# PIC16F1779 register map
Vendor: Microchip
Registers are 8-bit, read-write, reset 0x0 unless marked. A register's access mark holds for its fields unless they carry their own. Addresses are absolute, and some are shared; only a register's first bit layout is shown; [hi:lo] are bit positions; {n}, {i} and the like mark numbered series.

## SFR
0x00 INDF0 reset not defined — (power-on value xxxxxxxx)
0x01 INDF1 reset not defined — (power-on value xxxxxxxx)
0x02 PCL
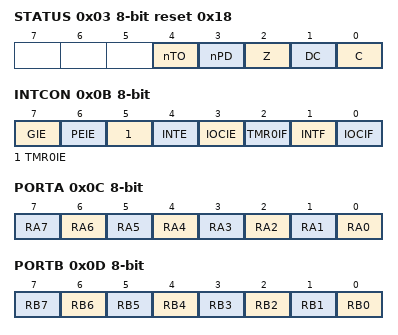
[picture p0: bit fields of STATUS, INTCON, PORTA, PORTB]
0x03 STATUS reset 0x18
  [4] nTO ro, [3] nPD ro, [2] Z, [1] DC, [0] C
0x04 FSR0L
0x05 FSR0H
0x06 FSR1L
0x07 FSR1H
0x08 BSR
  [4:0] BSR
0x09 WREG
  [7:0] WREG0
0x0A PCLATH
  [6:0] PCLATH
0x0B INTCON reset not defined — (power-on value 0000000x)
  [7] GIE, [6] PEIE, [5] TMR0IE, [4] INTE, [3] IOCIE, [2] TMR0IF, [1] INTF, [0] IOCIF ro
0x0C PORTA reset not defined — (power-on value xxxxxxxx)
  [n] RA{n} (n=0..7)
0x0D PORTB reset not defined — (power-on value xxxxxxxx)
  [n] RB{n} (n=0..7)
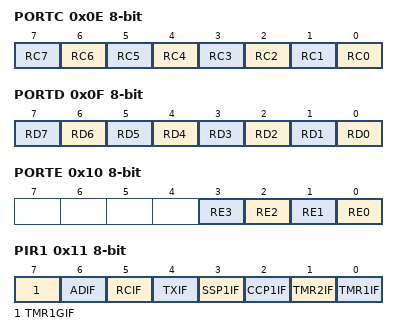
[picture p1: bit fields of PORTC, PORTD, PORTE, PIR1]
0x0E PORTC reset not defined — (power-on value xxxxxxxx)
  [n] RC{n} (n=0..7)
0x0F PORTD reset not defined — (power-on value xxxxxxxx)
  [n] RD{n} (n=0..7)
0x10 PORTE reset not defined — (power-on value ----xxxx)
  [n] RE{n} (n=0..3)
0x11 PIR1
  [7] TMR1GIF — Timer1 Gate Interrupt Flag bit
  [6] ADIF — A/D Converter Interrupt Flag bit
  [5] RCIF — EUSART Receive Interrupt Enable bit
  [4] TXIF — EUSART Transmit Interrupt Enable bit
  [3] SSP1IF — Synchronous Serial Port (MSSP) Interrupt Flag bit
  [2] CCP1IF
  [1] TMR2IF — TMR2 to PR2 Match Interrupt Flag bit
  [0] TMR1IF — TMR1 Overflow Interrupt Flag bit
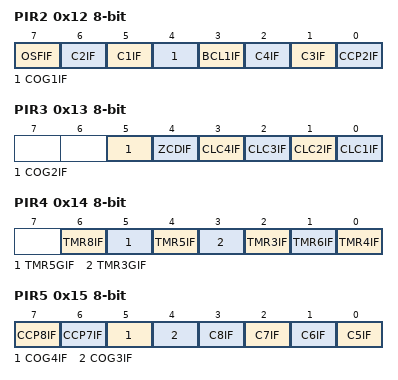
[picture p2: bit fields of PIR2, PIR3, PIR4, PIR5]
0x12 PIR2
  [7] OSFIF — Oscillator Fail Interrupt Enable bit
  [6] C2IF — Numerically Controlled Oscillator Flag bit
  [5] C1IF — Numerically Controlled Oscillator Flag bit
  [4] COG1IF
  [3] BCL1IF — MSSP Bus Collision Interrupt Flag bit
  [2] C4IF — Numerically Controlled Oscillator Flag bit
  [1] C3IF
  [0] CCP2IF
0x13 PIR3
  [5] COG2IF
  [4] ZCDIF
  [3] CLC4IF
  [2] CLC3IF — Configurable Logic Block Interrupt Flag
  [1] CLC2IF — Configurable Logic Block Interrupt Flag
  [0] CLC1IF — Configurable Logic Block Interrupt Flag
0x14 PIR4
  [6] TMR8IF, [5] TMR5GIF, [4] TMR5IF, [3] TMR3GIF, [2] TMR3IF, [1] TMR6IF, [0] TMR4IF
0x15 PIR5
  [7] CCP8IF, [6] CCP7IF, [5] COG4IF, [4] COG3IF, [n-5] C{n}IF (n=5..8)
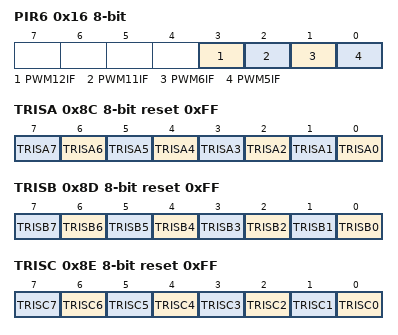
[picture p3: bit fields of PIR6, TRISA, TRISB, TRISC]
0x16 PIR6
  [3] PWM12IF, [2] PWM11IF, [1] PWM6IF, [0] PWM5IF
0x17 TMR0
0x8C TRISA reset 0xFF — PORTA Data Direction Control Register
  [n] TRISA{n} (n=0..7)
0x8D TRISB reset 0xFF
  [n] TRISB{n} (n=0..7)
0x8E TRISC reset 0xFF — PORTC Data Direction Control Register
  [n] TRISC{n} (n=0..7)
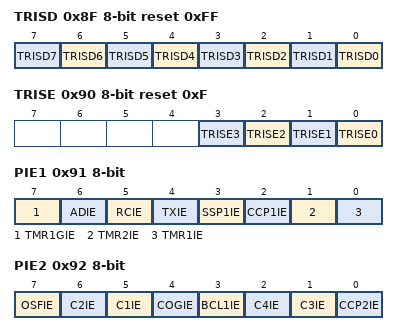
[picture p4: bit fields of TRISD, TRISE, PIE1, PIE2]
0x8F TRISD reset 0xFF
  [n] TRISD{n} (n=0..7)
0x90 TRISE reset 0xF
  [n] TRISE{n} (n=0..3)
0x91 PIE1 — Peripheral Interrupt Enable Register 1
  [7] TMR1GIE — Timer1 Gate Interrupt Enable bit
  [6] ADIE — A/D Converter Interrupt Enable bit
  [5] RCIE
  [4] TXIE
  [3] SSP1IE
  [2] CCP1IE
  [1] TMR2IE — TMR2 to PR2 Match Interrupt Enable bit
  [0] TMR1IE — TMR1 Overflow Interrupt Enable bit
0x92 PIE2 — Peripheral Interrupt Enable Register 2
  [7] OSFIE, [6] C2IE, [5] C1IE, [4] COGIE, [3] BCL1IE, [2] C4IE, [1] C3IE, [0] CCP2IE
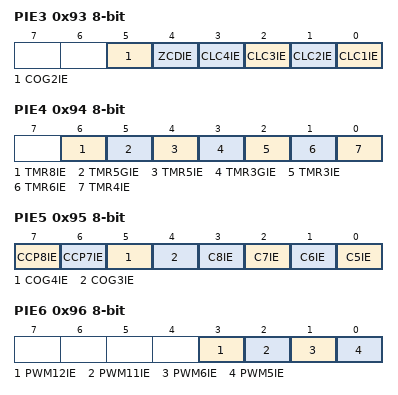
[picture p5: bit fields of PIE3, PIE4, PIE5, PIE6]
0x93 PIE3 — Peripheral Interrupt Enable Register 3
  [5] COG2IE, [4] ZCDIE, [n-1] CLC{n}IE (n=1..4)
0x94 PIE4
  [6] TMR8IE, [5] TMR5GIE, [4] TMR5IE, [3] TMR3GIE, [2] TMR3IE, [1] TMR6IE, [0] TMR4IE
0x95 PIE5 reset not defined — (power-on value x0x0xx00)
  [7] CCP8IE, [6] CCP7IE, [5] COG4IE, [4] COG3IE, [n-5] C{n}IE (n=5..8)
0x96 PIE6 reset not defined — (power-on value ----x000)
  [3] PWM12IE, [2] PWM11IE, [1] PWM6IE, [0] PWM5IE
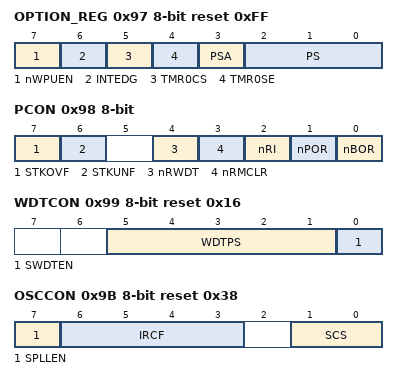
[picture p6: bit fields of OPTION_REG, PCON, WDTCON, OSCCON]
0x97 OPTION_REG reset 0xFF — Option Register
  [7] nWPUEN — Weak Pull-up Enable bit
  [6] INTEDG — Interrupt Edge Select bit
  [5] TMR0CS
  [4] TMR0SE — TMR0 Source Edge Select bit
  [3] PSA — Prescaler Active bit
  [2:0] PS
0x98 PCON reset not defined — Power Control Register (power-on value 00-111qq)
  [7] STKOVF — Stack Overflow Flag bit
  [6] STKUNF — Stack Underflow Flag bit
  [4] nRWDT
  [3] nRMCLR — MCLR Reset Flag bit
  [2] nRI — RESET Instruction Flag bit
  [1] nPOR — Power-on Reset Status bit
  [0] nBOR — Brown-out Reset Status bit
0x99 WDTCON reset 0x16 — Watchdog Timer Control Register
  [5:1] WDTPS
  [0] SWDTEN — Software Enable/Disable for Watch Dog Timer bit
0x9A OSCTUNE
  [5:0] TUN
0x9B OSCCON reset 0x38 — Oscillator Control Register
  [7] SPLLEN, [6:3] IRCF, [1:0] SCS
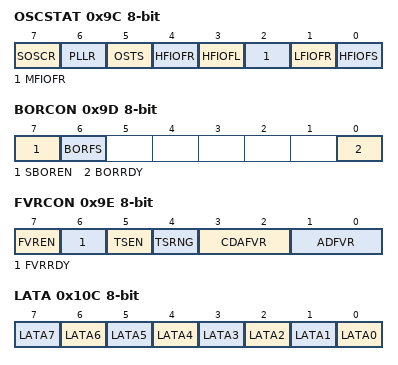
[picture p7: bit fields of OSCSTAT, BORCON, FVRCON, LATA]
0x9C OSCSTAT ro reset not defined — Oscillator Status Register (power-on value 0qq00q0q)
  [7] SOSCR
  [6] PLLR
  [5] OSTS — Oscillator Start-up Time-out Status bit
  [4] HFIOFR
  [3] HFIOFL
  [2] MFIOFR
  [1] LFIOFR — Low Freqency Internal Oscillator Ready bit
  [0] HFIOFS — Low Freqency Internal Oscillator Ready bit
0x9D BORCON reset not defined — (power-on value 10-----q)
  [7] SBOREN, [6] BORFS, [0] BORRDY ro
0x9E FVRCON reset not defined — (power-on value 0q000000)
  [7] FVREN, [6] FVRRDY ro, [5] TSEN, [4] TSRNG, [3:2] CDAFVR, [1:0] ADFVR
0x10C LATA reset not defined — (power-on value xxxxxxxx)
  [n] LATA{n} (n=0..7)
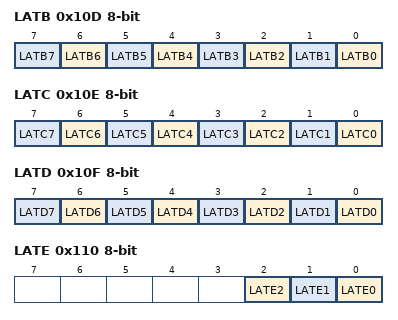
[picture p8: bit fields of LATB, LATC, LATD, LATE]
0x10D LATB reset not defined — (power-on value xxxxxxxx)
  [n] LATB{n} (n=0..7)
0x10E LATC reset not defined — (power-on value xxxxxxxx)
  [n] LATC{n} (n=0..7)
0x10F LATD reset not defined — (power-on value xxxxxxxx)
  [n] LATD{n} (n=0..7)
0x110 LATE reset not defined — (power-on value -----xxx)
  [2] LATE2, [1] LATE1, [0] LATE0
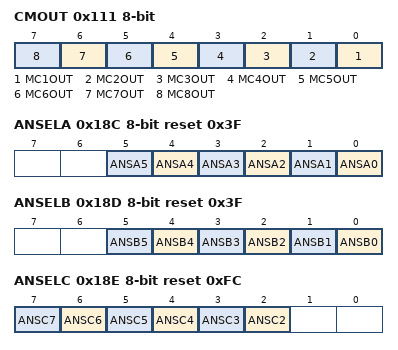
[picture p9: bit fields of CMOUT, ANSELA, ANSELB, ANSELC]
0x111 CMOUT ro
  [n-1] MC{n}OUT (n=1..8)
0x18C ANSELA reset 0x3F
  [n] ANSA{n} (n=0..5)
0x18D ANSELB reset 0x3F
  [n] ANSB{n} (n=0..5)
0x18E ANSELC reset 0xFC
  [n] ANSC{n} (n=2..7)
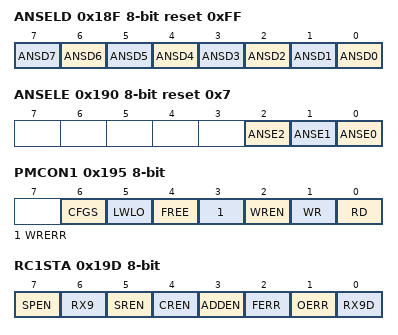
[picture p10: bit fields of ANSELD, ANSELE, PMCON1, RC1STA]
0x18F ANSELD reset 0xFF
  [n] ANSD{n} (n=0..7)
0x190 ANSELE reset 0x7
  [2] ANSE2, [1] ANSE1, [0] ANSE0
0x191 PMADRL
0x192 PMADRH reset 0x80
  [6:0] PMADRH
0x193 PMDATL reset not defined — (power-on value xxxxxxxx)
0x194 PMDATH reset not defined — (power-on value --xxxxxx)
  [5:0] PMDATH
0x195 PMCON1 reset not defined — (power-on value 1000x000)
  [6] CFGS — FLASH Program / Data EEPROM or Configuration Select bit
  [5] LWLO — Load Write Latches Only bit
  [4] FREE — Program FLASH Erase Enable bit
  [3] WRERR — Sequence Error Flag bit
  [2] WREN — Program/Erase Enable bit
  [1] WR — Write Control bit (can only be set)
  [0] RD — Read Control bit (can only be set)
0x196 PMCON2 wo
0x197 VREGCON reset 0x1
  [1] VREGPM
0x199 RC1REG ro
0x19A TX1REG
0x19B SP1BRGL
0x19C SP1BRGH
0x19D RC1STA
  [7] SPEN, [6] RX9, [5] SREN, [4] CREN, [3] ADDEN, [2] FERR ro, [1] OERR ro, [0] RX9D ro
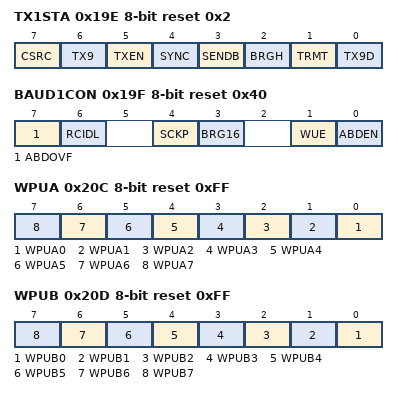
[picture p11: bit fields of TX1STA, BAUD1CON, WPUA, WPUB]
0x19E TX1STA reset 0x2
  [7] CSRC, [6] TX9, [5] TXEN, [4] SYNC, [3] SENDB, [2] BRGH, [1] TRMT ro, [0] TX9D
0x19F BAUD1CON reset 0x40
  [7] ABDOVF ro, [6] RCIDL ro, [4] SCKP, [3] BRG16, [1] WUE, [0] ABDEN
0x20C WPUA reset 0xFF
  [n] WPUA{n} (n=0..7)
0x20D WPUB reset 0xFF
  [n] WPUB{n} (n=0..7)
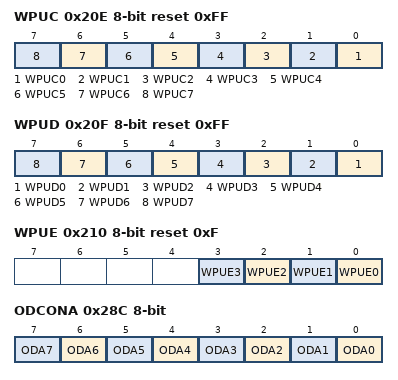
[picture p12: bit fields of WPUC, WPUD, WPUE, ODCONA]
0x20E WPUC reset 0xFF
  [n] WPUC{n} (n=0..7)
0x20F WPUD reset 0xFF
  [n] WPUD{n} (n=0..7)
0x210 WPUE reset 0xF
  [n] WPUE{n} (n=0..3)
0x28C ODCONA
  [n] ODA{n} (n=0..7)
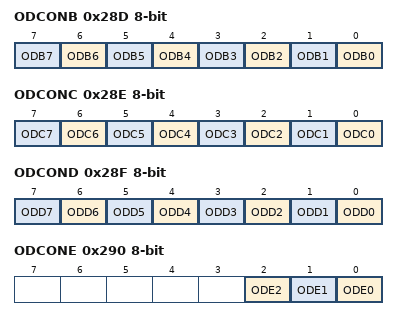
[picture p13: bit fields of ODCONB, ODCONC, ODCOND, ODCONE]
0x28D ODCONB
  [n] ODB{n} (n=0..7)
0x28E ODCONC
  [n] ODC{n} (n=0..7)
0x28F ODCOND
  [n] ODD{n} (n=0..7)
0x290 ODCONE
  [2] ODE2, [1] ODE1, [0] ODE0
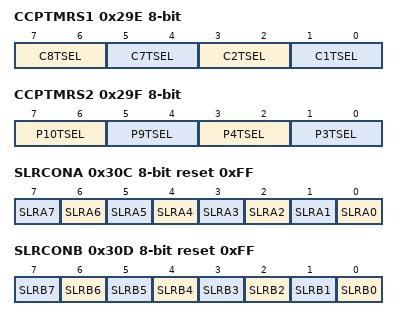
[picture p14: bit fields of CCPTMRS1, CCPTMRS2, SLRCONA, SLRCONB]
0x29E CCPTMRS1
  [7:6] C8TSEL, [5:4] C7TSEL, [3:2] C2TSEL, [1:0] C1TSEL
0x29F CCPTMRS2
  [7:6] P10TSEL, [5:4] P9TSEL, [3:2] P4TSEL, [1:0] P3TSEL
0x30C SLRCONA reset 0xFF
  [n] SLRA{n} (n=0..7)
0x30D SLRCONB reset 0xFF
  [n] SLRB{n} (n=0..7)
0x30E SLRCONC reset 0xFF
  [n] SLRC{n} (n=0..7)
0x30F SLRCOND reset 0xFF
  [n] SLRD{n} (n=0..7)
0x310 SLRCONE reset 0x7
  [2] SLRE2, [1] SLRE1, [0] SLRE0
0x38C INLVLA reset 0xFF
  [n] INLVLA{n} (n=0..7)
0x38D INLVLB reset 0xFF
  [n] INLVLB{n} (n=0..7)
0x38E INLVLC reset 0xFF
  [n] INLVLC{n} (n=0..7)
0x38F INLVLD reset 0xFF
  [n] INLVLD{n} (n=0..7)
0x390 INLVLE reset 0xF
  [n] INLVLE{n} (n=0..3)
0x391 IOCAP
  [n] IOCAP{n} (n=0..7)
0x392 IOCAN
  [n] IOCAN{n} (n=0..7)
0x393 IOCAF
  [n] IOCAF{n} (n=0..7)
0x394 IOCBP
  [n] IOCBP{n} (n=0..7)
0x395 IOCBN
  [n] IOCBN{n} (n=0..7)
0x396 IOCBF
  [n] IOCBF{n} (n=0..7)
0x397 IOCCP
  [n] IOCCP{n} (n=0..7)
0x398 IOCCN
  [n] IOCCN{n} (n=0..7)
0x399 IOCCF
  [n] IOCCF{n} (n=0..7)
0x39D IOCEP
  [3] IOCEP3
0x39E IOCEN
  [3] IOCEN3
0x39F IOCEF
  [3] IOCEF3
0x40D HIDRVB
  [1] HIDB1, [0] HIDB0
0x48E ADRESL reset not defined — (power-on value xxxxxxxx)
  [7:0] ADRES
0x48F ADRESH reset not defined — (power-on value xxxxxxxx)
  [7:0] ADRES
0x490 ADCON0
  [7:2] CHS, [1] GO, [0] ADON
0x491 ADCON1
  [7] ADFM, [6:4] ADCS, [2] ADNREF, [1:0] ADPREF
0x492 ADCON2
  [5:0] TRIGSEL
0x58D DACLD reset not defined — (power-on value --x0--00)
  [5] DAC6LD, [4] DAC5LD, [1] DAC2LD, [0] DAC1LD
0xD8E PWMEN
  [3] MPWM12EN, [2] MPWM11EN, [1] MPWM6EN, [0] MPWM5EN
0xD8F PWMLD
  [3] MPWM12LD, [2] MPWM11LD, [1] MPWM6LD, [0] MPWM5LD
0xD90 PWMOUT reset not defined — (power-on value ----0x00)
  [3] MPWM12OUT, [2] MPWM11OUT, [1] MPWM6OUT, [0] MPWM5OUT
0xE0C PPSLOCK
  [0] PPSLOCKED
0xE0D INTPPS reset 0x8
  [5:0] INTPPS
0xE0E T0CKIPPS reset 0x4
  [5:0] T0CKIPPS
0xE0F T1CKIPPS reset 0x10
  [5:0] T1CKIPPS
0xE10 T1GPPS reset 0xD
  [5:0] T1GPPS
0xE11 T3CKIPPS reset 0x10
  [5:0] T3CKIPPS
0xE12 T3GPPS reset 0x10
  [5:0] T3GPPS
0xE13 T5CKIPPS reset 0x12
  [5:0] T5CKIPPS
0xE14 T5GPPS reset 0xC
  [5:0] T5GPPS
0xE15 T2INPPS reset 0x13
  [5:0] T2INPPS
0xE16 T4INPPS reset 0x15
  [5:0] T4INPPS
0xE17 T6INPPS reset 0xF
  [5:0] T6INPPS
0xE18 T8INPPS reset 0x14
  [5:0] T8INPPS
0xE19 CCP1PPS reset 0x12
  [5:0] CCP1PPS
0xE1A CCP2PPS reset 0x11
  [5:0] CCP2PPS
0xE1B CCP7PPS reset 0xD
  [5:0] CCP7PPS
0xE1C CCP8PPS reset 0x8
  [5:0] CCP8PPS
0xE1D COG1INPPS reset 0x8
  [5:0] COG1INPPS
0xE1E COG2INPPS reset 0x9
  [5:0] COG2INPPS
0xE1F COG3INPPS reset 0xA
  [5:0] COG3INPPS
0xE20 COG4INPPS reset 0xA
  [5:0] COG4INPPS
0xE21 MD1CLPPS reset 0x4
  [5:0] MD1CLPPS
0xE22 MD1CHPPS reset 0x3
  [5:0] MD1CHPPS
0xE23 MD1MODPPS reset 0x5
  [5:0] MD1MODPPS
0xE24 MD2CLPPS reset 0x4
  [5:0] MD2CLPPS
0xE25 MD2CHPPS reset 0x3
  [5:0] MD2CHPPS
0xE26 MD2MODPPS reset 0x5
  [5:0] MD2MODPPS
0xE27 MD3CLPPS reset 0xC
  [5:0] MD3CLPPS
0xE28 MD3CHPPS reset 0xB
  [5:0] MD3CHPPS
0xE29 MD3MODPPS reset 0xD
  [5:0] MD3MODPPS
0xE2A MD4CLPPS reset 0xC
  [5:0] MD4CLPPS
0xE2B MD4CHPPS reset 0xB
  [5:0] MD4CHPPS
0xE2C MD4MODPPS reset 0xA
  [5:0] MD4MODPPS
0xE2D PRG1RPPS reset 0x4
  [5:0] PRG1RPPS
0xE2E PRG1FPPS reset 0x5
  [5:0] PRG1FPPS
0xE2F PRG2RPPS reset 0x11
  [5:0] PRG2RPPS
0xE30 PRG2FPPS reset 0x12
  [5:0] PRG2FPPS
0xE31 PRG3RPPS reset 0x14
  [5:0] PRG3RPPS
0xE32 PRG3FPPS reset 0x15
  [5:0] PRG3FPPS
0xE33 PRG4RPPS reset 0x14
  [5:0] PRG4RPPS
0xE34 PRG4FPPS reset 0x15
  [5:0] PRG4FPPS
0xE35 CLCIN0PPS
  [5:0] CLCIN0PPS
0xE36 CLCIN1PPS reset 0x1
  [5:0] CLCIN1PPS
0xE37 CLCIN2PPS reset 0xE
  [5:0] CLCIN2PPS
0xE38 CLCIN3PPS reset 0xF
  [5:0] CLCIN3PPS
0xE39 ADCACTPPS reset 0xC
  [5:0] ADCACTPPS
0xE3A SSPCLKPPS reset 0x13
  [5:0] SSPCLKPPS
0xE3B SSPDATPPS reset 0x14
  [5:0] SSPDATPPS
0xE3C SSPSSPPS reset 0x5
  [5:0] SSPSSPPS
0xE3D RXPPS reset 0x17
  [5:0] RXPPS
0xE3E CKPPS reset 0x16
  [5:0] CKPPS
{0xE90+i} RA{i}PPS (i=0..7)
  [5:0] RA{i}PPS
{0xE98+i} RB{i}PPS (i=0..7)
  [5:0] RB{i}PPS
{0xEA0+i} RC{i}PPS (i=0..7)
  [5:0] RC{i}PPS
{0xEA8+i} RD{i}PPS (i=0..7)
  [5:0] RD{i}PPS
{0xEB0+i} RE{i}PPS (i=0..2)
  [5:0] RE{i}PPS
0xF0F CLCDATA reset not defined — (power-on value ----x000)
  [3] MLC4OUT, [2] MCLC3OUT ro, [1] MCLC2OUT ro, [0] MCLC1OUT ro
0xFE4 STATUS_SHAD reset not defined — (power-on value -----xxx)
  [2] Z_SHAD, [1] DC_SHAD, [0] C_SHAD
0xFE5 WREG_SHAD reset not defined — (power-on value xxxxxxxx)
0xFE6 BSR_SHAD reset not defined — (power-on value ---xxxxx)
  [4:0] BSR_SHAD
0xFE7 PCLATH_SHAD reset not defined — (power-on value -xxxxxxx)
  [6:0] PCLATH_SHAD
0xFE8 FSR0L_SHAD reset not defined — (power-on value xxxxxxxx)
0xFE9 FSR0H_SHAD reset not defined — (power-on value xxxxxxxx)
0xFEA FSR1L_SHAD reset not defined — (power-on value xxxxxxxx)
0xFEB FSR1H_SHAD reset not defined — (power-on value xxxxxxxx)
0xFED STKPTR reset 0x1F
  [4:0] STKPTR
0xFEE TOSL reset not defined — (power-on value xxxxxxxx)
0xFEF TOSH reset not defined — (power-on value -xxxxxxx)
  [6:0] TOSH
